# UPD70F3508 register map
Vendor: Renesas; Series: V850E2/Px4; File version: 1.0
CPU: other r0p0, little endian, no MPU, FPU, 4 interrupt priority bits
Registers are 8-bit, read-write, reset 0x0 unless marked. A register's access mark holds for its fields unless they carry their own. Offsets are from the block's base; [hi:lo] are bit positions; {n}, {i} and the like mark numbered series.

## TAUA0 — Timer Array Unit A 0
Base 0xFF808000
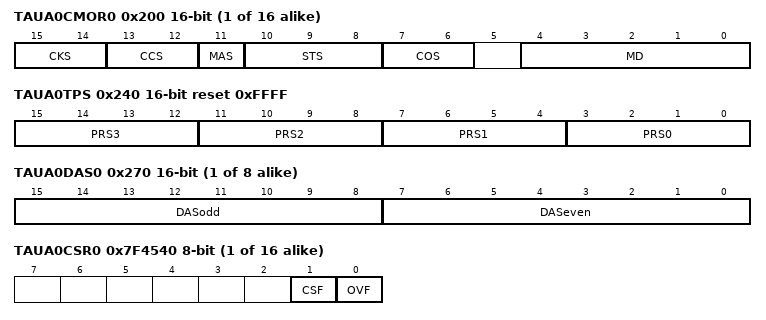
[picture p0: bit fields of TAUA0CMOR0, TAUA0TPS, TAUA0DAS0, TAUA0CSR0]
{0x200+4i} TAUA0CMOR{i} 16-bit (i=0..15) — TAUA0 Channel Mode OS Register {i}
  [15:14] CKS — Sampling clock select [1:0]
  [13:12] CCS — Count clock select [1:0]
  [11] MAS — Master/slave select (even ch only)
  [10:8] STS — External start trigger select [2:0]
  [7:6] COS — Capture update timing [1:0]
  [4:0] MD — Operating mode [4:0]
0x240 TAUA0TPS 16-bit reset 0xFFFF — TAUA0 Prescaler Clock Select Register
  [15:12] PRS3 — CK3_PRE prescaler select [3:0]
  [11:8] PRS2 — CK2 prescaler select [3:0]
  [7:4] PRS1 — CK1 prescaler select [3:0]
  [3:0] PRS0 — CK0 prescaler select [3:0]
0x244 TAUA0BRS — TAUA0 Prescaler Baud Rate Setting Register
  [7:0] BRS — CK3 division coefficient [7:0]
0x248 TAUA0TOM 16-bit — TAUA0 Channel Output Mode Register
  [15:0] TOMm — Output mode per channel: 0=independent 1=synchronous
0x24C TAUA0TOC 16-bit — TAUA0 Channel Output Configuration Register
  [15:0] TOCm — Output config per channel: 0=mode1 1=mode2
0x250 TAUA0TDE 16-bit — TAUA0 Channel Dead Time Output Enable Register
  [15:0] TDEm — Dead time enable per channel
0x254 TAUA0TDM 16-bit — TAUA0 Channel Dead Time Output Mode Register
  [15:0] TDMm — Dead time mode per channel: 0=duty 1=TIN-edge
0x258 TAUA0TRE 16-bit — TAUA0 Channel Real-Time Output Enable Register
  [15:0] TREm — Real-time output enable per channel
0x25C TAUA0TRC 16-bit — TAUA0 Channel Real-Time Output Control Register
  [15:0] TRCm — Real-time trigger channel: 0=next upper 1=self
0x260 TAUA0RDE 16-bit — TAUA0 Channel Reload Data Enable Register
  [15:0] RDEm — Simultaneous rewrite enable per channel
0x264 TAUA0RDM 16-bit — TAUA0 Channel Reload Data Mode Register
  [15:0] RDMm — Simultaneous rewrite timing: 0=master-start 1=triangle-peak
0x268 TAUA0RDS 16-bit — TAUA0 Channel Reload Data Control Channel Select Register
  [15:0] RDSm — Rewrite trigger source per channel: 0=master 1=upper
0x26C TAUA0RDC 16-bit — TAUA0 Channel Reload Data Control Register
  [15:0] RDCm — Simultaneous rewrite trigger channel select
{0x270+4i} TAUA0DAS{i} 16-bit (i=0..7) — TAUA0 DMA Window Address Setting Register {i}
  [15:8] DASodd — Odd channel DMA window address [15:8]
  [7:0] DASeven — Even channel DMA window address [7:0]
{0x7F4400+4i} TAUA0CDR{i} 16-bit (i=0..15) — TAUA0 Channel Data Register {i}
  [15:0] CDR — Capture/compare data [15:0]
0x7F4440 TAUA0TOL 16-bit — TAUA0 Channel Output Active Level Register
  [15:0] TOLm — Output logic per channel: 0=positive 1=inverted
0x7F4444 TAUA0RDT 16-bit wo — TAUA0 Channel Reload Data Trigger Register
  [15:0] RDTm — Trigger simultaneous rewrite pending per channel
0x7F4448 TAUA0RSF 16-bit ro — TAUA0 Channel Reload Status Register
  [15:0] RSFm — Simultaneous rewrite pending status per channel
0x7F444C TAUA0TRO 16-bit — TAUA0 Channel Real-Time Output Register
  [15:0] TROm — Real-time output value per channel: 0=low 1=high
0x7F4450 TAUA0TME 16-bit — TAUA0 Channel Modulation Output Enable Register
  [15:0] TMEm — Modulation output enable per channel
0x7F4454 TAUA0TDL 16-bit — TAUA0 Channel Dead Time Output Level Register
  [15:0] TDLm — Dead time phase per channel: 0=normal 1=reverse
0x7F4458 TAUA0TO 16-bit — TAUA0 Channel Output Register
  [15:0] TOm — Output level per channel: 0=low 1=high
0x7F445C TAUA0TOE 16-bit — TAUA0 Channel Output Enable Register
  [15:0] TOEm — Timer output enable per channel
{0x7F4480+4i} TAUA0CNT{i} 16-bit ro (i=0..15) — TAUA0 Channel Counter Register {i}
  [15:0] CNT — 16-bit counter value
{0x7F44C0+4i} TAUA0CMUR{i} (i=0..15) — TAUA0 Channel Mode User Register {i}
  [1:0] TIS — TIN valid edge select: 00=fall 01=rise 10=both-low 11=both-high
{0x7F4500+4i} TAUA0DWR{i} 16-bit (i=0..15) — TAUA0 DMA Window Register {i}
{0x7F4540+4i} TAUA0CSR{i} ro (i=0..15) — TAUA0 Channel Status Register {i}
  [1] CSF — Count direction: 0=up 1=down
  [0] OVF — Counter overflow flag
{0x7F4580+4i} TAUA0CSC{i} wo (i=0..15) — TAUA0 Channel Status Clear Trigger Register {i}
  [0] CLOV — Clear overflow flag (write 1)
0x7F45C0 TAUA0TE 16-bit ro — TAUA0 Channel Enable Status Register
  [15:0] TEm — Counter enable status per channel
0x7F45C4 TAUA0TS 16-bit wo — TAUA0 Channel Start Trigger Register
  [15:0] TSm — Start counter per channel (write 1)
0x7F45C8 TAUA0TT 16-bit wo — TAUA0 Channel Stop Trigger Register
  [15:0] TTm — Stop counter per channel (write 1)
